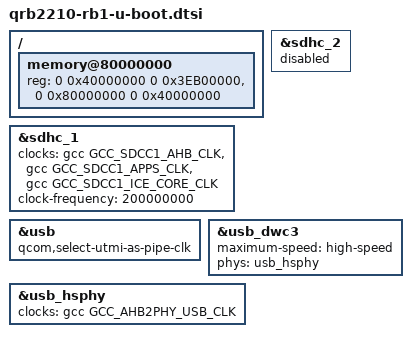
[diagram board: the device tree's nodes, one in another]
/ {
	/* When running as the primary bootloader there is no prior
	 * stage to populate the memory layout for us. We *should*
	 * have two nodes here, but ABL does NOT like that.
	 * sooo we're stuck with this.
	 */
	memory@80000000 {
		device_type = "memory";
		reg = <0 0x40000000 0 0x3EB00000>,
		      <0 0x80000000 0 0x40000000>;
	};
};

&sdhc_1 {
	/* Remove rpmcc clocks */
	clocks = <&gcc GCC_SDCC1_AHB_CLK>,
		 <&gcc GCC_SDCC1_APPS_CLK>,
		 <&gcc GCC_SDCC1_ICE_CORE_CLK>;
	clock-names = "iface", "core", "ice";

	clock-frequency = <200000000>;
};

&sdhc_2 {
	status = "disabled";
};

&usb {
	qcom,select-utmi-as-pipe-clk;
};

&usb_dwc3 {
	maximum-speed = "high-speed";

	/* We don't support superspeed in u-boot so remove the SSPHY */
	phys = <&usb_hsphy>;
	phy-names = "usb2-phy";
};

&usb_hsphy {
	/* Disable ref clk because rpmcc isn't supported */
	clocks = <&gcc GCC_AHB2PHY_USB_CLK>;
	clock-names = "cfg_ahb";
};
